# M030GAE register map
File version: 1.0
Registers are 32-bit, read-write, reset 0x0 unless marked. A register's access mark holds for its fields unless they carry their own. Offsets are from the block's base; [hi:lo] are bit positions; {n}, {i} and the like mark numbered series; 'fields as' and 'values as' point back to an identical list.

## BPWM1 — BPWM Register Map
Base 0x4005B000
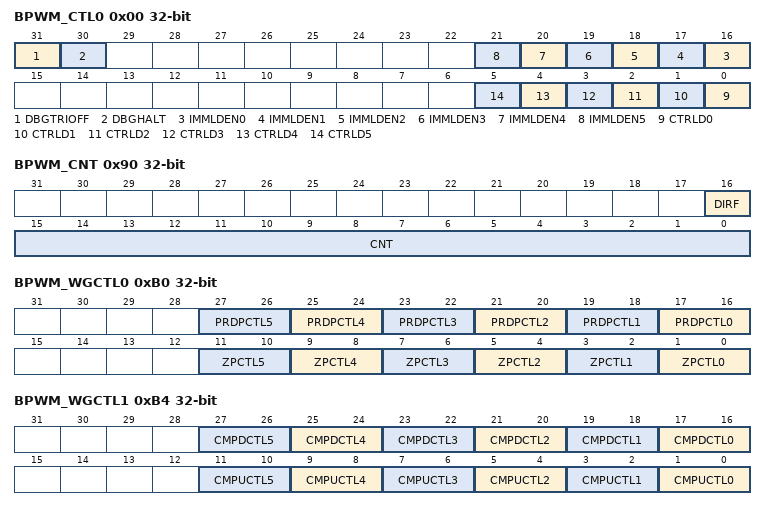
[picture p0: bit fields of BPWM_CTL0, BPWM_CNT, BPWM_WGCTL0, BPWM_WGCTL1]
0x00 BPWM_CTL0 — BPWM Control Register 0
  [31] DBGTRIOFF — ICE Debug Mode Acknowledge Disable (Write Protect). BPWM pin will keep output no matter ICE debug mode acknowledged or not. Note: This bit is write protected. Refer to SYS_REGLCTL register.
    0=ICE debug mode acknowledgement effects BPWM output; 1=ICE debug mode acknowledgement Disabled
  [30] DBGHALT — ICE Debug Mode Counter Halt (Write Protect). If counter halt is enabled, BPWM all counters will keep current value until exit ICE debug mode. Note: This bit is write protected. Refer to SYS_REGLCTL register.
    0=ICE debug mode counter halt Disabled; 1=ICE debug mode counter halt Enabled
  [n+16] IMMLDEN{n} (n=0..5) — Immediately Load Enable Bits. Each bit n controls the corresponding BPWM channel n. Note: If IMMLDENn is enabled, CTRLDn will be invalid.
    0=PERIOD will load to PBUF at the end point of each period. CMPDAT will load to CMPBUF at the end point or center point of each period by setting CTRLD bit; 1=PERIOD/CMPDAT will load to PBUF and CMPBUF immediately when software update PERIOD/CMPDAT
  [n] CTRLD{n} (n=0..5) — Center Re-load. Each bit n controls the corresponding BPWM channel n. In up-down counter type, PERIOD will load to PBUF at the end point of each period. CMPDAT will load to CMPBUF at the center point of a period.
0x04 BPWM_CTL1 — BPWM Control Register 1
  [1:0] CNTTYPE0 — BPWM Counter Behavior Type 0. Each bit n controls corresponding BPWM channel n.
    0=Up counter type (supports in capture mode); 1=Down count type (supports in capture mode); 2=Up-down counter type
0x10 BPWM_CLKSRC — BPWM Clock Source Register
  [2:0] ECLKSRC0 — BPWM_CH01 External Clock Source Select
    0=BPWM1_CLK; {v}=TIMER{v-1} overflow (v=1..6)
0x14 BPWM_CLKPSC — BPWM Clock Prescale Register
  [11:0] CLKPSC — BPWM Counter Clock Prescale. The clock of BPWM counter is decided by clock prescaler. All BPWM channels share one BPWM counter clock prescaler. The clock of BPWM counter is divided by (CLKPSC+ 1).
0x20 BPWM_CNTEN — BPWM Counter Enable Register
  [0] CNTEN0 — BPWM Counter 0 Enable Bit
    0=BPWM Counter and clock prescaler stop running; 1=BPWM Counter and clock prescaler start running
0x24 BPWM_CNTCLR — BPWM Clear Counter Register
  [0] CNTCLR0 — Clear BPWM Counter Control Bit 0. It is automatically cleared by hardware.
    0=No effect; 1=Clear 16-bit BPWM counter to 0000H
0x30 BPWM_PERIOD
  [15:0] PERIOD — BPWM Period Register. Up-Count mode: In this mode, BPWM counter counts from 0 to PERIOD, and restarts from 0. Down-Count mode: In this mode, BPWM counter counts from PERIOD to 0, and restarts from PERIOD.
{0x50+4i} BPWM_CMPDAT{i} (i=0..5) — BPWM Comparator Register {i}
  [15:0] CMPDAT — BPWM Comparator Register. CMPDAT is used to compare with CNT to generate BPWM waveform, interrupt and trigger ADC. In independent mode, CMPDAT0~5 are denoted as 6 independent BPWM_CH0~5 compared points.
0x90 BPWM_CNT ro — BPWM Counter Register
  [16] DIRF — BPWM Direction Indicator Flag (Read Only)
    0=Counter is Down counting; 1=Counter is UP counting
  [15:0] CNT — BPWM Data Register (Read Only). User can monitor CNT to know the current value in 16-bit period counter.
0xB0 BPWM_WGCTL0 — BPWM Generation Register 0
  [2n+17:2n+16] PRDPCTL{n} (n=0..5) — BPWM Period Point Control. Each bit n controls the corresponding BPWM channel n. BPWM can control output level when BPWM counter count to (PERIOD+1). Note: This bit is center point control when BPWM counter is operating in up-down counter type.
    0=Do nothing; 1=BPWM period point output Low; 2=BPWM period point output High; 3=BPWM period point output Toggle
  [2n+1:2n] ZPCTL{n} (n=0..5) — BPWM Zero Point Control. Each bit n controls the corresponding BPWM channel n. BPWM can control output level when BPWM counter counts to 0.
    0=Do nothing; 1=BPWM zero point output Low; 2=BPWM zero point output High; 3=BPWM zero point output Toggle
0xB4 BPWM_WGCTL1 — BPWM Generation Register 1
  [2n+17:2n+16] CMPDCTL{n} (n=0..5) — BPWM Compare Down Point Control. Each bit n controls the corresponding BPWM channel n. BPWM can control output level when BPWM counter down count to CMPDAT.
    0=Do nothing; 1=BPWM compare down point output Low; 2=BPWM compare down point output High; 3=BPWM compare down point output Toggle
  [2n+1:2n] CMPUCTL{n} (n=0..5) — BPWM Compare Up Point Control. Each bit n controls the corresponding BPWM channel n. BPWM can control output level when BPWM counter up count to CMPDAT.
    0=Do nothing; 1=BPWM compare up point output Low; 2=BPWM compare up point output High; 3=BPWM compare up point output Toggle
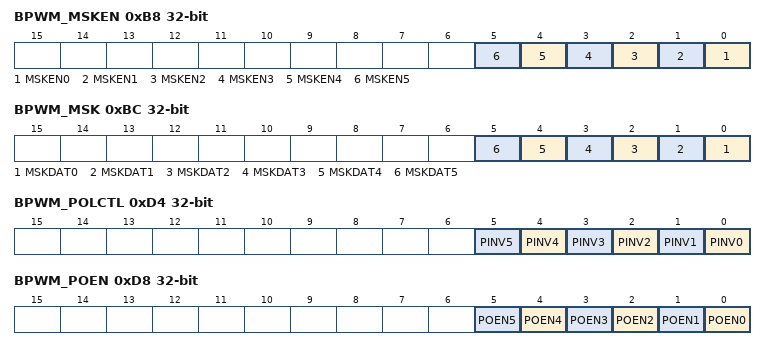
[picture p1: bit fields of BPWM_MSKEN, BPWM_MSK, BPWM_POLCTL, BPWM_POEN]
0xB8 BPWM_MSKEN — BPWM Mask Enable Register
  [all] fields
    0=BPWM output signal is non-masked; 1=BPWM output signal is masked and output MSKDATn data
  [n] MSKEN{n} (n=0..5) — BPWM Mask Enable Bits. Each bit n controls the corresponding BPWM channel n. The BPWM output signal will be masked when this bit is enabled. The corresponding BPWM channel n will output MSKDATn (BPWM_MSK[5:0]) data.
0xBC BPWM_MSK — BPWM Mask Data Register
  [all] fields
    0=Output logic low to BPWMn; 1=Output logic high to BPWMn
  [n] MSKDAT{n} (n=0..5) — BPWM Mask Data Bit. This data bit control the state of BPWMn output pin, if corresponding mask function is enabled. Each bit n controls the corresponding BPWM channel n.
0xD4 BPWM_POLCTL — BPWM Pin Polar Inverse Register
  [all] fields
    0=BPWM output polar inverse Disabled; 1=BPWM output polar inverse Enabled
  [n] PINV{n} (n=0..5) — BPWM PIN Polar Inverse Control. The register controls polarity state of BPWM output. Each bit n controls the corresponding BPWM channel n.
0xD8 BPWM_POEN — BPWM Output Enable Register
  [all] fields
    0=BPWM pin at tri-state; 1=BPWM pin in output mode
  [n] POEN{n} (n=0..5) — BPWM Pin Output Enable Bits. Each bit n controls the corresponding BPWM channel n.
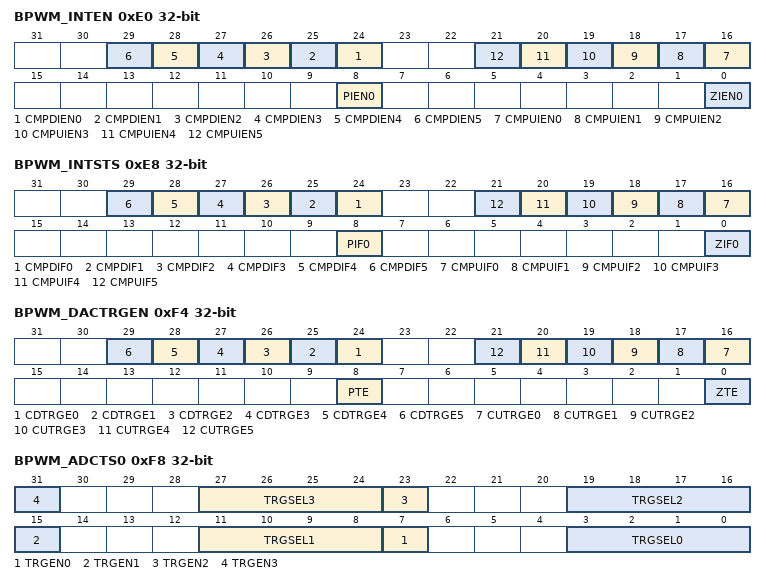
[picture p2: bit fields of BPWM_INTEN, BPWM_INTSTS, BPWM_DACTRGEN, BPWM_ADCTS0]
0xE0 BPWM_INTEN — BPWM Interrupt Enable Register
  [n+24] CMPDIEN{n} (n=0..5) — BPWM Compare Down Count Interrupt Enable Bits. Each bit n controls the corresponding BPWM channel n.
    0=Compare down count interrupt Disabled; 1=Compare down count interrupt Enabled
  [n+16] CMPUIEN{n} (n=0..5) — BPWM Compare Up Count Interrupt Enable Bits. Each bit n controls the corresponding BPWM channel n.
    0=Compare up count interrupt Disabled; 1=Compare up count interrupt Enabled
  [8] PIEN0 — BPWM Period Point Interrupt 0 Enable Bit. Note: When up-down counter type period point means center point.
    0=Period point interrupt Disabled; 1=Period point interrupt Enabled
  [0] ZIEN0 — BPWM Zero Point Interrupt 0 Enable Bit
    0=Zero point interrupt Disabled; 1=Zero point interrupt Enabled
0xE8 BPWM_INTSTS — BPWM Interrupt Flag Register
  [n+24] CMPDIF{n} (n=0..5) — BPWM Compare Down Count Interrupt Flag. Each bit n controls the corresponding BPWM channel n. Flag is set by hardware when BPWM counter down count and reaches BPWM_CMPDATn, software can clear this bit by writing 1 to it. Each bit n controls the corresponding BPWM channel n. Note: If CMPDAT is equal to PERIOD, this flag is not working in down counter type selection.
  [n+16] CMPUIF{n} (n=0..5) — BPWM Compare Up Count Interrupt Flag. Flag is set by hardware when BPWM counter up count and reaches BPWM_CMPDATn, software can clear this bit by writing 1 to it. Each bit n controls the corresponding BPWM channel n. Note: If CMPDAT is equal to PERIOD, this flag is not working in up counter type selection.
  [8] PIF0 — BPWM Period Point Interrupt Flag. This bit is set by hardware when BPWM counter reaches BPWM_PERIOD, software can write 1 to clear this bit to 0.
  [0] ZIF0 — BPWM Zero Point Interrupt Flag. This bit is set by hardware when BPWM counter reaches 0, software can write 1 to clear this bit to 0.
0xF4 BPWM_DACTRGEN — BPWM Trigger DAC Enable Register
  [n+24] CDTRGE{n} (n=0..5) — BPWM Compare Down Count Point Trigger DAC Enable Bits. BPWM can trigger DAC to start action when BPWM counter down count to CMP if this bit is set to1. Note 1: This bit should keep at 0 when BPWM counter operating in up counter type. Note 2: In complementary mode, CDTRGEN1, 3, 5 is used as another CDTRGEN for channel 0, 2, 4.
    0=BPWM Compare Down count point trigger DAC function Disabled; 1=BPWM Compare Down count point trigger DAC function Enabled
  [n+16] CUTRGE{n} (n=0..5) — BPWM Compare Up Count Point Trigger DAC Enable Bits. BPWM can trigger DAC to start action when BPWM counter counts up to CMP if this bit is set to1. Note: This bit should keep at 0 when BPWM counter operating in down counter type..
    0=BPWM Compare Up point trigger DAC function Disabled; 1=BPWM Compare Up point trigger DAC function Enabled
  [8] PTE — BPWM Period Point Trigger DAC Enable Bits. BPWM can trigger DAC to start action when BPWM counter counts up to (PERIODn+1) if this bit is set to1.
    0=BPWM period point trigger DAC function Disabled; 1=BPWM period point trigger DAC function Enabled
  [0] ZTE — BPWM Zero Point Trigger DAC Enable Bits. BPWM can trigger DAC to start action when BPWM counter down count to zero if this bit is set to1.
    values as PTE
0xF8 BPWM_ADCTS0 — BPWM Trigger ADC Source Select Register 0
  [8n+7] TRGEN{n} (n=0..3) — BPWM_CH{n} Trigger ADC Enable Bit
    0=BPWM_CH{n} Trigger EADC function Disabled; 1=BPWM_CH{n} Trigger EADC function Enabled
  [27:24] TRGSEL3 — BPWM_CH3 Trigger ADC Source Select. Others reserved.
    0=BPWM_CH2 zero point; 1=BPWM_CH2 period point; 2=BPWM_CH2 zero or period point; 3=BPWM_CH2 up-count CMPDAT point; 4=BPWM_CH2 down-count CMPDAT point; 8=BPWM_CH3 up-count CMPDAT point; 9=BPWM_CH3 down-count CMPDAT point
  [19:16] TRGSEL2 — BPWM_CH2 Trigger ADC Source Select. Others reserved
    values as TRGSEL3
  [11:8] TRGSEL1 — BPWM_CH1 Trigger ADC Source Select. Others reserved
    0=BPWM_CH0 zero point; 1=BPWM_CH0 period point; 2=BPWM_CH0 zero or period point; 3=BPWM_CH0 up-count CMPDAT point; 4=BPWM_CH0 down-count CMPDAT point; 8=BPWM_CH1 up-count CMPDAT point; 9=BPWM_CH1 down-count CMPDAT point
  [3:0] TRGSEL0 — BPWM_CH0 Trigger ADC Source Select. Others reserved
    values as TRGSEL1
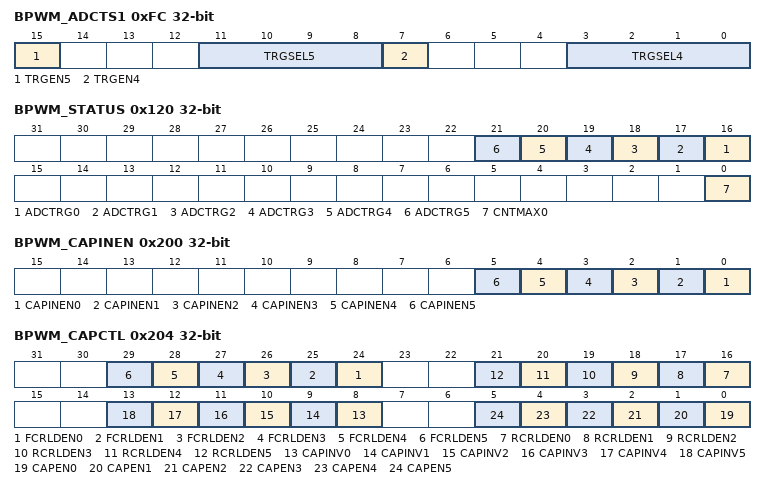
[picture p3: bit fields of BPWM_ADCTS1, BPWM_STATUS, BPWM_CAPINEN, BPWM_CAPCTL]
0xFC BPWM_ADCTS1 — BPWM Trigger ADC Source Select Register 1
  [15] TRGEN5 — BPWM_CH5 Trigger ADC Enable Bit
    0=BPWM_CH5 Trigger EADC function Disabled; 1=BPWM_CH5 Trigger EADC function Enabled
  [11:8] TRGSEL5 — BPWM_CH5 Trigger ADC Source Select. Others reserved
    0=BPWM_CH4 zero point; 1=BPWM_CH4 period point; 2=BPWM_CH4 zero or period point; 3=BPWM_CH4 up-count CMPDAT point; 4=BPWM_CH4 down-count CMPDAT point; 8=BPWM_CH5 up-count CMPDAT point; 9=BPWM_CH5 down-count CMPDAT point
  [7] TRGEN4 — BPWM_CH4 Trigger ADC Enable Bit
    0=BPWM_CH4 Trigger EADC function Disabled; 1=BPWM_CH4 Trigger EADC function Enabled
  [3:0] TRGSEL4 — BPWM_CH4 Trigger ADC Source Select. Others reserved
    values as TRGSEL5
0x120 BPWM_STATUS
  [n+16] ADCTRG{n} (n=0..5) — ADC Start of Conversion Status. Each bit n controls the corresponding BPWM channel n.
    0=No ADC start of conversion trigger event has occurred; 1=An ADC start of conversion trigger event has occurred. Software can write 1 to clear this bit
  [0] CNTMAX0 — Time-base Counter 0 Equal to 0xFFFF Latched Status
    0=The time-base counter never reached its maximum value 0xFFFF; 1=The time-base counter reached its maximum value. Software can write 1 to clear this bit
0x200 BPWM_CAPINEN — BPWM Capture Input Enable Register
  [all] fields
    0=BPWM Channel capture input path Disabled. The input of BPWM channel capture function is always regarded as 0; 1=BPWM Channel capture input path Enabled. The input of BPWM channel capture function comes from correlative multifunction pin
  [n] CAPINEN{n} (n=0..5) — Capture Input Enable Bits. Each bit n controls the corresponding BPWM channel n.
0x204 BPWM_CAPCTL — BPWM Capture Control Register
  [n+24] FCRLDEN{n} (n=0..5) — Falling Capture Reload Enable Bits. Each bit n controls the corresponding BPWM channel n.
    0=Falling capture reload counter Disabled; 1=Falling capture reload counter Enabled
  [n+16] RCRLDEN{n} (n=0..5) — Rising Capture Reload Enable Bits. Each bit n controls the corresponding BPWM channel n.
    0=Rising capture reload counter Disabled; 1=Rising capture reload counter Enabled
  [n+8] CAPINV{n} (n=0..5) — Capture Inverter Enable Bits. Each bit n controls the corresponding BPWM channel n.
    0=Capture source inverter Disabled; 1=Capture source inverter Enabled. Reverse the input signal from GPIO
  [n] CAPEN{n} (n=0..5) — Capture Function Enable Bits. Each bit n controls the corresponding BPWM channel n.
    0=Capture function Disabled. RCAPDAT/FCAPDAT register will not be updated; 1=Capture function Enabled. Capture latched the BPWM counter value when detected rising or falling edge of input signal and saved to RCAPDAT (Rising latch) and FCAPDAT (Falling latch)
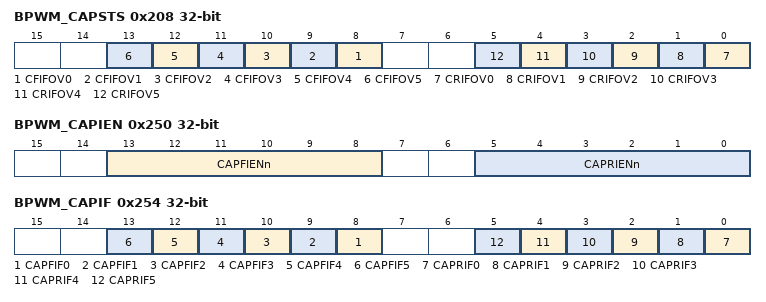
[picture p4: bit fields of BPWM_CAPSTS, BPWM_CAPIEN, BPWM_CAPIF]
0x208 BPWM_CAPSTS ro — BPWM Capture Status Register
  [n+8] CFIFOV{n} (n=0..5) — Capture Falling Interrupt Flag Overrun Status (Read Only). This flag indicates if falling latch happened when the corresponding CAPFIF is 1. Each bit n controls the corresponding BPWM channel n. Note: This bit will be cleared automatically when user clear corresponding CAPFIF.
  [n] CRIFOV{n} (n=0..5) — Capture Rising Interrupt Flag Overrun Status (Read Only). This flag indicates if rising latch happened when the corresponding CAPRIF is 1. Each bit n controls the corresponding BPWM channel n. Note: This bit will be cleared automatically when user clear corresponding CAPRIF.
{0x20C+8i} BPWM_RCAPDAT{i} ro (i=0..5) — BPWM Rising Capture Data Register {i}
  [15:0] RCAPDAT — BPWM Rising Capture Data (Read Only). When rising capture condition happened, the BPWM counter value will be saved in this register.
{0x210+8i} BPWM_FCAPDAT{i} ro (i=0..5) — BPWM Falling Capture Data Register {i}
  [15:0] FCAPDAT — BPWM Falling Capture Data (Read Only). When falling capture condition happened, the BPWM counter value will be saved in this register.
0x250 BPWM_CAPIEN — BPWM Capture Interrupt Enable Register
  [13:8] CAPFIENn — BPWM Capture Falling Latch Interrupt Enable Bits. Each bit n controls the corresponding BPWM channel n.
    0=Capture falling edge latch interrupt Disabled; 1=Capture falling edge latch interrupt Enabled
  [5:0] CAPRIENn — BPWM Capture Rising Latch Interrupt Enable Bits. Each bit n controls the corresponding BPWM channel n.
    0=Capture rising edge latch interrupt Disabled; 1=Capture rising edge latch interrupt Enabled
0x254 BPWM_CAPIF — BPWM Capture Interrupt Flag Register
  [n+8] CAPFIF{n} (n=0..5) — BPWM Capture Falling Latch Interrupt Flag. Each bit n controls the corresponding BPWM channel n. Note: This bit is cleared by writing 1 to it.
    0=No capture falling latch condition happened; 1=Capture falling latch condition happened, this flag will be set to high
  [n] CAPRIF{n} (n=0..5) — BPWM Capture Rising Latch Interrupt Flag. Each bit n controls the corresponding BPWM channel n. Note: This bit is cleared by writing 1 to it.
    0=No capture rising latch condition happened; 1=Capture rising latch condition happened, this flag will be set to high
0x304 BPWM_PBUF ro — BPWM PERIOD Buffer
  [15:0] PBUF — BPWM Period Buffer (Read Only). Used as PERIOD active register.
{0x31C+4i} BPWM_CMPBUF{i} ro (i=0..5) — BPWM CMPDAT {i} Buffer
  [15:0] CMPBUF — BPWM Comparator Buffer (Read Only). Used as CMP active register.
